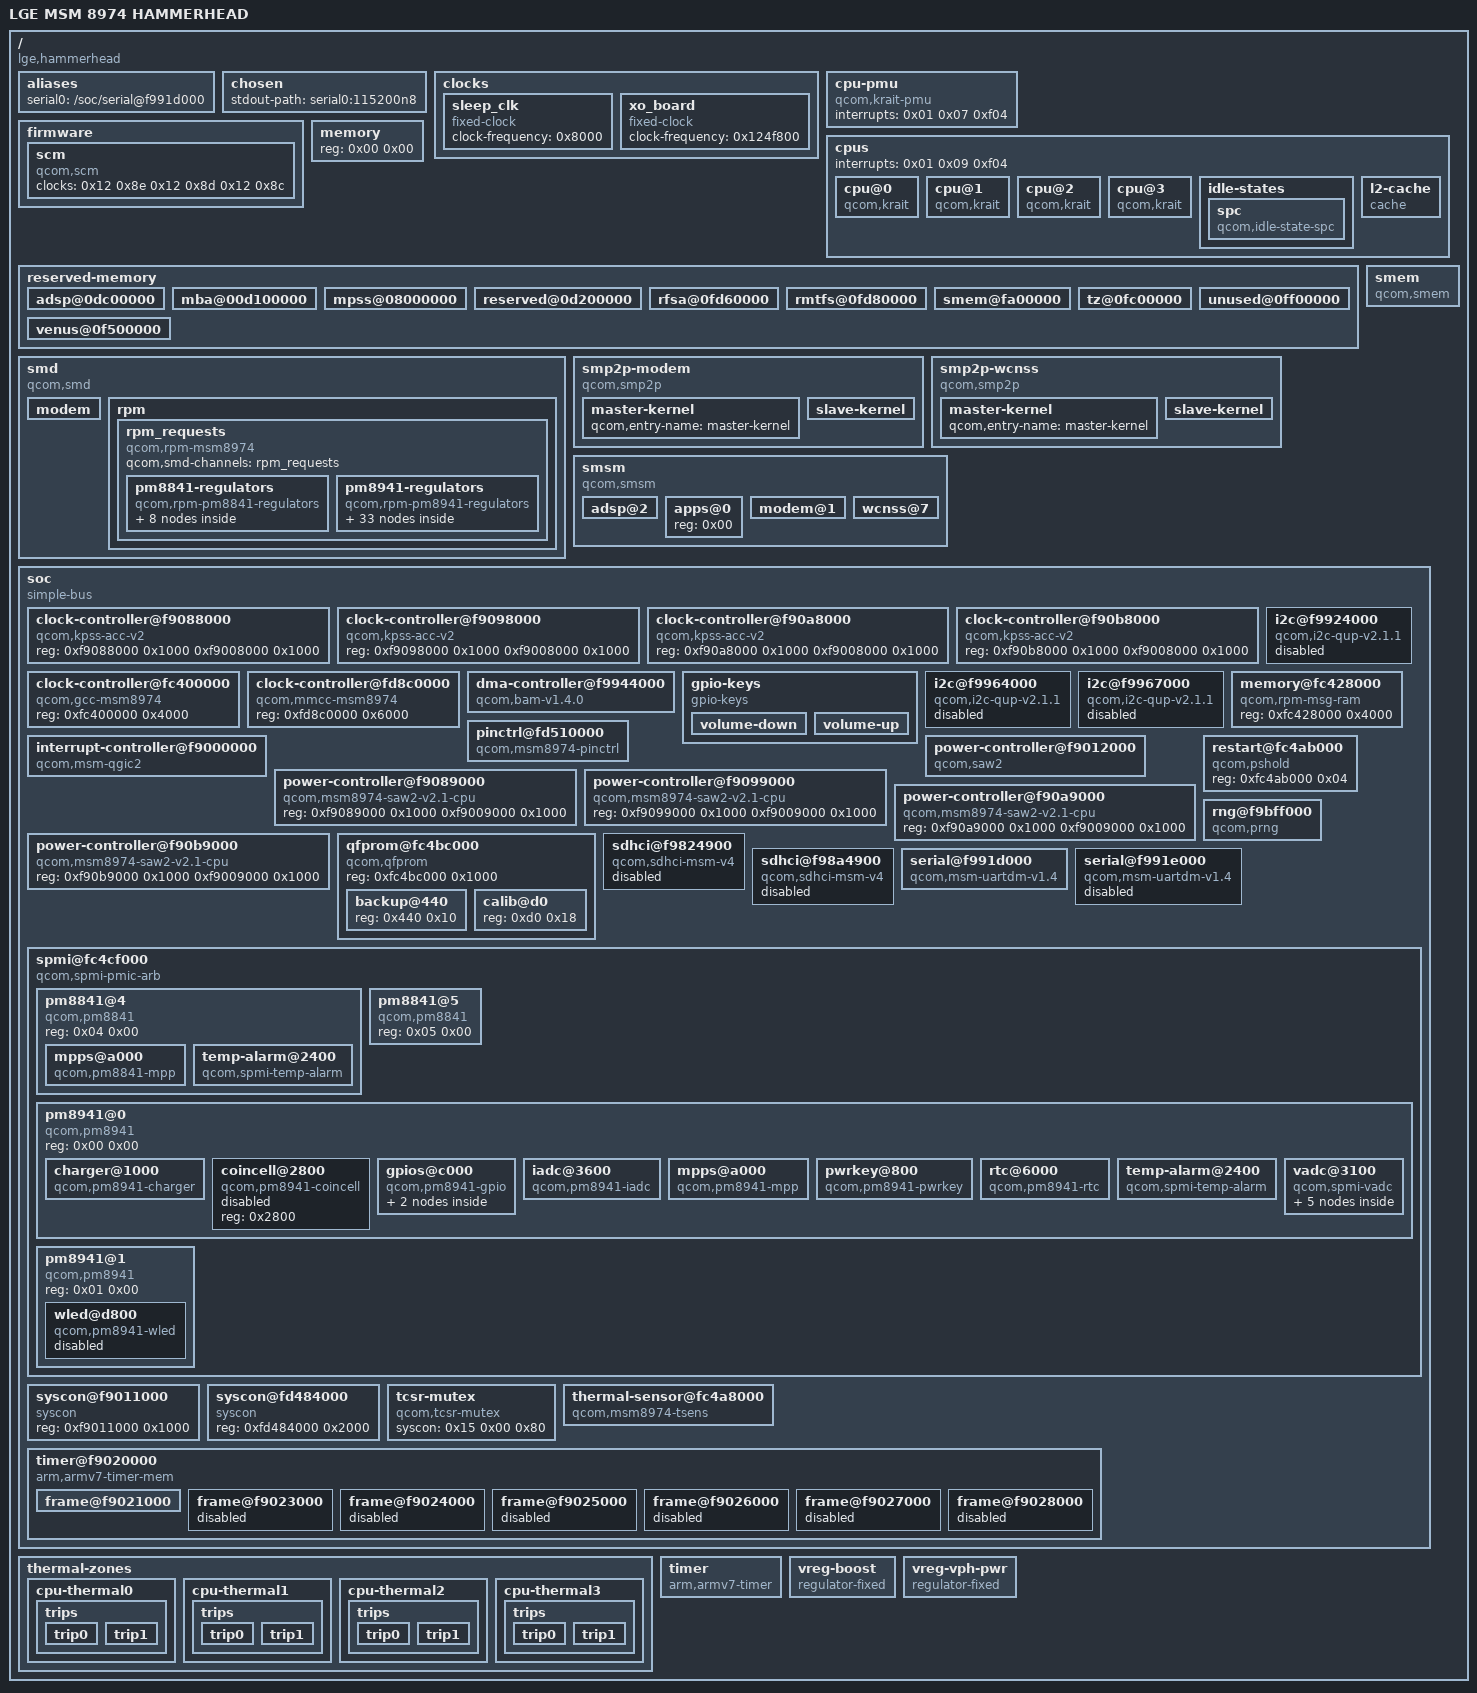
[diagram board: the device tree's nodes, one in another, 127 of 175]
/dts-v1/;

/ {
	#address-cells = <0x01>;
	#size-cells = <0x01>;
	compatible = "lge,hammerhead\0qcom,msm8974";
	interrupt-parent = <0x01>;
	model = "LGE MSM 8974 HAMMERHEAD";

	__symbols__ {
		CPU_SPC = "/cpus/idle-states/spc";
		L2 = "/cpus/l2-cache";
		acc0 = "/soc/clock-controller@f9088000";
		acc1 = "/soc/clock-controller@f9098000";
		acc2 = "/soc/clock-controller@f90a8000";
		acc3 = "/soc/clock-controller@f90b8000";
		adsp_smsm = "/smsm/adsp@2";
		apcs = "/soc/syscon@f9011000";
		apps_smsm = "/smsm/apps@0";
		blsp1_uart1 = "/soc/serial@f991d000";
		blsp1_uart2 = "/soc/serial@f991e000";
		blsp2_dma = "/soc/dma-controller@f9944000";
		blsp_i2c11 = "/soc/i2c@f9967000";
		blsp_i2c8 = "/soc/i2c@f9964000";
		boost_bypass_n_pin = "/soc/spmi@fc4cf000/pm8941@0/gpios@c000/boost-bypass";
		cpu_alert0 = "/thermal-zones/cpu-thermal0/trips/trip0";
		cpu_alert1 = "/thermal-zones/cpu-thermal1/trips/trip0";
		cpu_alert2 = "/thermal-zones/cpu-thermal2/trips/trip0";
		cpu_alert3 = "/thermal-zones/cpu-thermal3/trips/trip0";
		cpu_crit0 = "/thermal-zones/cpu-thermal0/trips/trip1";
		cpu_crit1 = "/thermal-zones/cpu-thermal1/trips/trip1";
		cpu_crit2 = "/thermal-zones/cpu-thermal2/trips/trip1";
		cpu_crit3 = "/thermal-zones/cpu-thermal3/trips/trip1";
		gcc = "/soc/clock-controller@fc400000";
		gpio_keys_pin_a = "/soc/spmi@fc4cf000/pm8941@0/gpios@c000/gpio-keys-active";
		intc = "/soc/interrupt-controller@f9000000";
		mmcc = "/soc/clock-controller@fd8c0000";
		modem_smp2p_in = "/smp2p-modem/slave-kernel";
		modem_smp2p_out = "/smp2p-modem/master-kernel";
		modem_smsm = "/smsm/modem@1";
		msmgpio = "/soc/pinctrl@fd510000";
		pm8841_0 = "/soc/spmi@fc4cf000/pm8841@4";
		pm8841_1 = "/soc/spmi@fc4cf000/pm8841@5";
		pm8841_mpps = "/soc/spmi@fc4cf000/pm8841@4/mpps@a000";
		pm8841_s1 = "/smd/rpm/rpm_requests/pm8841-regulators/s1";
		pm8841_s2 = "/smd/rpm/rpm_requests/pm8841-regulators/s2";
		pm8841_s3 = "/smd/rpm/rpm_requests/pm8841-regulators/s3";
		pm8841_s4 = "/smd/rpm/rpm_requests/pm8841-regulators/s4";
		pm8841_s5 = "/smd/rpm/rpm_requests/pm8841-regulators/s5";
		pm8841_s6 = "/smd/rpm/rpm_requests/pm8841-regulators/s6";
		pm8841_s7 = "/smd/rpm/rpm_requests/pm8841-regulators/s7";
		pm8841_s8 = "/smd/rpm/rpm_requests/pm8841-regulators/s8";
		pm8941_0 = "/soc/spmi@fc4cf000/pm8941@0";
		pm8941_1 = "/soc/spmi@fc4cf000/pm8941@1";
		pm8941_5v = "/smd/rpm/rpm_requests/pm8941-regulators/s4";
		pm8941_5vs1 = "/smd/rpm/rpm_requests/pm8941-regulators/5vs1";
		pm8941_5vs2 = "/smd/rpm/rpm_requests/pm8941-regulators/5vs2";
		pm8941_gpios = "/soc/spmi@fc4cf000/pm8941@0/gpios@c000";
		pm8941_iadc = "/soc/spmi@fc4cf000/pm8941@0/iadc@3600";
		pm8941_l1 = "/smd/rpm/rpm_requests/pm8941-regulators/l1";
		pm8941_l10 = "/smd/rpm/rpm_requests/pm8941-regulators/l10";
		pm8941_l11 = "/smd/rpm/rpm_requests/pm8941-regulators/l11";
		pm8941_l12 = "/smd/rpm/rpm_requests/pm8941-regulators/l12";
		pm8941_l13 = "/smd/rpm/rpm_requests/pm8941-regulators/l13";
		pm8941_l14 = "/smd/rpm/rpm_requests/pm8941-regulators/l14";
		pm8941_l15 = "/smd/rpm/rpm_requests/pm8941-regulators/l15";
		pm8941_l16 = "/smd/rpm/rpm_requests/pm8941-regulators/l16";
		pm8941_l17 = "/smd/rpm/rpm_requests/pm8941-regulators/l17";
		pm8941_l18 = "/smd/rpm/rpm_requests/pm8941-regulators/l18";
		pm8941_l19 = "/smd/rpm/rpm_requests/pm8941-regulators/l19";
		pm8941_l2 = "/smd/rpm/rpm_requests/pm8941-regulators/l2";
		pm8941_l20 = "/smd/rpm/rpm_requests/pm8941-regulators/l20";
		pm8941_l21 = "/smd/rpm/rpm_requests/pm8941-regulators/l21";
		pm8941_l22 = "/smd/rpm/rpm_requests/pm8941-regulators/l22";
		pm8941_l23 = "/smd/rpm/rpm_requests/pm8941-regulators/l23";
		pm8941_l24 = "/smd/rpm/rpm_requests/pm8941-regulators/l24";
		pm8941_l3 = "/smd/rpm/rpm_requests/pm8941-regulators/l3";
		pm8941_l4 = "/smd/rpm/rpm_requests/pm8941-regulators/l4";
		pm8941_l5 = "/smd/rpm/rpm_requests/pm8941-regulators/l5";
		pm8941_l6 = "/smd/rpm/rpm_requests/pm8941-regulators/l6";
		pm8941_l7 = "/smd/rpm/rpm_requests/pm8941-regulators/l7";
		pm8941_l8 = "/smd/rpm/rpm_requests/pm8941-regulators/l8";
		pm8941_l9 = "/smd/rpm/rpm_requests/pm8941-regulators/l9";
		pm8941_lvs1 = "/smd/rpm/rpm_requests/pm8941-regulators/lvs1";
		pm8941_lvs2 = "/smd/rpm/rpm_requests/pm8941-regulators/lvs2";
		pm8941_lvs3 = "/smd/rpm/rpm_requests/pm8941-regulators/lvs3";
		pm8941_mpps = "/soc/spmi@fc4cf000/pm8941@0/mpps@a000";
		pm8941_s1 = "/smd/rpm/rpm_requests/pm8941-regulators/s1";
		pm8941_s2 = "/smd/rpm/rpm_requests/pm8941-regulators/s2";
		pm8941_s3 = "/smd/rpm/rpm_requests/pm8941-regulators/s3";
		pm8941_temp = "/soc/spmi@fc4cf000/pm8941@0/temp-alarm@2400";
		pm8941_vadc = "/soc/spmi@fc4cf000/pm8941@0/vadc@3100";
		pm8941_wled = "/soc/spmi@fc4cf000/pm8941@1/wled@d800";
		qfprom = "/soc/qfprom@fc4bc000";
		rpm_msg_ram = "/soc/memory@fc428000";
		saw0 = "/soc/power-controller@f9089000";
		saw1 = "/soc/power-controller@f9099000";
		saw2 = "/soc/power-controller@f90a9000";
		saw3 = "/soc/power-controller@f90b9000";
		saw_l2 = "/soc/power-controller@f9012000";
		smem_region = "/reserved-memory/smem@fa00000";
		soc = "/soc";
		spmi_bus = "/soc/spmi@fc4cf000";
		tcsr_mutex = "/soc/tcsr-mutex";
		tcsr_mutex_block = "/soc/syscon@fd484000";
		tsens = "/soc/thermal-sensor@fc4a8000";
		tsens_backup = "/soc/qfprom@fc4bc000/backup@440";
		tsens_calib = "/soc/qfprom@fc4bc000/calib@d0";
		vreg_boost = "/vreg-boost";
		vreg_vph_pwr = "/vreg-vph-pwr";
		wcnss_smp2p_in = "/smp2p-wcnss/slave-kernel";
		wcnss_smp2p_out = "/smp2p-wcnss/master-kernel";
		wcnss_smsm = "/smsm/wcnss@7";
	};

	aliases {
		serial0 = "/soc/serial@f991d000";
	};

	chosen {
		stdout-path = "serial0:115200n8";
	};

	clocks {

		sleep_clk {
			#clock-cells = <0x00>;
			clock-frequency = <0x8000>;
			compatible = "fixed-clock";
		};

		xo_board {
			#clock-cells = <0x00>;
			clock-frequency = <0x124f800>;
			compatible = "fixed-clock";
		};
	};

	cpu-pmu {
		compatible = "qcom,krait-pmu";
		interrupts = <0x01 0x07 0xf04>;
	};

	cpus {
		#address-cells = <0x01>;
		#size-cells = <0x00>;
		interrupts = <0x01 0x09 0xf04>;

		cpu@0 {
			compatible = "qcom,krait";
			cpu-idle-states = <0x05>;
			device_type = "cpu";
			enable-method = "qcom,kpss-acc-v2";
			next-level-cache = <0x02>;
			qcom,acc = <0x03>;
			qcom,saw = <0x04>;
			reg = <0x00>;
		};

		cpu@1 {
			compatible = "qcom,krait";
			cpu-idle-states = <0x05>;
			device_type = "cpu";
			enable-method = "qcom,kpss-acc-v2";
			next-level-cache = <0x02>;
			qcom,acc = <0x06>;
			qcom,saw = <0x07>;
			reg = <0x01>;
		};

		cpu@2 {
			compatible = "qcom,krait";
			cpu-idle-states = <0x05>;
			device_type = "cpu";
			enable-method = "qcom,kpss-acc-v2";
			next-level-cache = <0x02>;
			qcom,acc = <0x08>;
			qcom,saw = <0x09>;
			reg = <0x02>;
		};

		cpu@3 {
			compatible = "qcom,krait";
			cpu-idle-states = <0x05>;
			device_type = "cpu";
			enable-method = "qcom,kpss-acc-v2";
			next-level-cache = <0x02>;
			qcom,acc = <0x0a>;
			qcom,saw = <0x0b>;
			reg = <0x03>;
		};

		idle-states {

			spc {
				compatible = "qcom,idle-state-spc\0arm,idle-state";
				entry-latency-us = <0x96>;
				exit-latency-us = <0xc8>;
				min-residency-us = <0x7d0>;
				phandle = <0x05>;
			};
		};

		l2-cache {
			cache-level = <0x02>;
			compatible = "cache";
			phandle = <0x02>;
			qcom,saw = <0x0c>;
		};
	};

	firmware {

		scm {
			clock-names = "core\0bus\0iface";
			clocks = <0x12 0x8e 0x12 0x8d 0x12 0x8c>;
			compatible = "qcom,scm";
		};
	};

	memory {
		device_type = "memory";
		reg = <0x00 0x00>;
	};

	reserved-memory {
		#address-cells = <0x01>;
		#size-cells = <0x01>;
		ranges;

		adsp@0dc00000 {
			no-map;
			reg = <0xdc00000 0x1900000>;
		};

		mba@00d100000 {
			no-map;
			reg = <0xd100000 0x100000>;
		};

		mpss@08000000 {
			no-map;
			reg = <0x8000000 0x5100000>;
		};

		reserved@0d200000 {
			no-map;
			reg = <0xd200000 0xa00000>;
		};

		rfsa@0fd60000 {
			no-map;
			reg = <0xfd60000 0x20000>;
		};

		rmtfs@0fd80000 {
			no-map;
			reg = <0xfd80000 0x180000>;
		};

		smem@fa00000 {
			no-map;
			phandle = <0x0e>;
			reg = <0xfa00000 0x200000>;
		};

		tz@0fc00000 {
			no-map;
			reg = <0xfc00000 0x160000>;
		};

		unused@0ff00000 {
			no-map;
			reg = <0xff00000 0x10100000>;
		};

		venus@0f500000 {
			no-map;
			reg = <0xf500000 0x500000>;
		};
	};

	smd {
		compatible = "qcom,smd";

		modem {
			interrupts = <0x00 0x19 0x01>;
			qcom,ipc = <0x11 0x08 0x0c>;
			qcom,smd-edge = <0x00>;
		};

		rpm {
			interrupts = <0x00 0xa8 0x01>;
			qcom,ipc = <0x11 0x08 0x00>;
			qcom,smd-edge = <0x0f>;

			rpm_requests {
				compatible = "qcom,rpm-msm8974";
				qcom,smd-channels = "rpm_requests";

				pm8841-regulators {
					compatible = "qcom,rpm-pm8841-regulators";

					s1 {
						phandle = <0x42>;
						regulator-max-microvolt = <0x100590>;
						regulator-min-microvolt = <0xa4cb8>;
					};

					s2 {
						phandle = <0x43>;
						regulator-max-microvolt = <0x100590>;
						regulator-min-microvolt = <0x7a120>;
					};

					s3 {
						phandle = <0x44>;
						regulator-max-microvolt = <0x100590>;
						regulator-min-microvolt = <0x100590>;
					};

					s4 {
						phandle = <0x45>;
						regulator-max-microvolt = <0xdbba0>;
						regulator-min-microvolt = <0xc6f98>;
					};

					s5 {
						phandle = <0x46>;
					};

					s6 {
						phandle = <0x47>;
					};

					s7 {
						phandle = <0x48>;
					};

					s8 {
						phandle = <0x49>;
					};
				};

				pm8941-regulators {
					compatible = "qcom,rpm-pm8941-regulators";
					vdd_l13_l20_l23_l24-supply = <0x1e>;
					vdd_l1_l3-supply = <0x1a>;
					vdd_l21-supply = <0x1e>;
					vdd_l2_lvs1_2_3-supply = <0x1b>;
					vdd_l4_l11-supply = <0x1a>;
					vdd_l5_l7-supply = <0x1c>;
					vdd_l6_l12_l14_l15-supply = <0x1c>;
					vdd_l8_l16_l18_l19-supply = <0x1d>;
					vdd_l9_l10_l17_l22-supply = <0x1e>;

					5vs1 {
						phandle = <0x66>;
					};

					5vs2 {
						phandle = <0x67>;
					};

					l1 {
						phandle = <0x4b>;
						regulator-always-on;
						regulator-boot-on;
						regulator-max-microvolt = <0x12b128>;
						regulator-min-microvolt = <0x12b128>;
					};

					l10 {
						phandle = <0x54>;
						regulator-max-microvolt = <0x2d0370>;
						regulator-min-microvolt = <0x1b7740>;
					};

					l11 {
						phandle = <0x55>;
						regulator-max-microvolt = <0x13d620>;
						regulator-min-microvolt = <0x13d620>;
					};

					l12 {
						phandle = <0x56>;
						regulator-always-on;
						regulator-boot-on;
						regulator-max-microvolt = <0x1b7740>;
						regulator-min-microvolt = <0x1b7740>;
					};

					l13 {
						phandle = <0x57>;
						regulator-boot-on;
						regulator-max-microvolt = <0x2d0370>;
						regulator-min-microvolt = <0x1b7740>;
					};

					l14 {
						phandle = <0x58>;
						regulator-max-microvolt = <0x1b7740>;
						regulator-min-microvolt = <0x1b7740>;
					};

					l15 {
						phandle = <0x59>;
						regulator-max-microvolt = <0x1f47d0>;
						regulator-min-microvolt = <0x1f47d0>;
					};

					l16 {
						phandle = <0x5a>;
						regulator-max-microvolt = <0x2932e0>;
						regulator-min-microvolt = <0x2932e0>;
					};

					l17 {
						phandle = <0x5b>;
						regulator-max-microvolt = <0x2b7cd0>;
						regulator-min-microvolt = <0x2b7cd0>;
					};

					l18 {
						phandle = <0x5c>;
						regulator-max-microvolt = <0x2b7cd0>;
						regulator-min-microvolt = <0x2b7cd0>;
					};

					l19 {
						phandle = <0x5d>;
						regulator-max-microvolt = <0x325aa0>;
						regulator-min-microvolt = <0x2dc6c0>;
					};

					l2 {
						phandle = <0x4c>;
						regulator-max-microvolt = <0x124f80>;
						regulator-min-microvolt = <0x124f80>;
					};

					l20 {
						phandle = <0x5e>;
						regulator-allow-set-load;
						regulator-boot-on;
						regulator-max-microvolt = <0x2d0370>;
						regulator-min-microvolt = <0x2d0370>;
						regulator-system-load = <0x30d40>;
					};

					l21 {
						phandle = <0x5f>;
						regulator-boot-on;
						regulator-max-microvolt = <0x2d0370>;
						regulator-min-microvolt = <0x2d0370>;
					};

					l22 {
						phandle = <0x60>;
						regulator-max-microvolt = <0x325aa0>;
						regulator-min-microvolt = <0x2dc6c0>;
					};

					l23 {
						phandle = <0x61>;
						regulator-max-microvolt = <0x2dc6c0>;
						regulator-min-microvolt = <0x2dc6c0>;
					};

					l24 {
						phandle = <0x62>;
						regulator-boot-on;
						regulator-max-microvolt = <0x2eebb8>;
						regulator-min-microvolt = <0x2eebb8>;
					};

					l3 {
						phandle = <0x4d>;
						regulator-max-microvolt = <0x12b128>;
						regulator-min-microvolt = <0x12b128>;
					};

					l4 {
						phandle = <0x4e>;
						regulator-max-microvolt = <0x12b128>;
						regulator-min-microvolt = <0x12b128>;
					};

					l5 {
						phandle = <0x4f>;
						regulator-max-microvolt = <0x1b7740>;
						regulator-min-microvolt = <0x1b7740>;
					};

					l6 {
						phandle = <0x50>;
						regulator-boot-on;
						regulator-max-microvolt = <0x1b7740>;
						regulator-min-microvolt = <0x1b7740>;
					};

					l7 {
						phandle = <0x51>;
						regulator-boot-on;
						regulator-max-microvolt = <0x1b7740>;
						regulator-min-microvolt = <0x1b7740>;
					};

					l8 {
						phandle = <0x52>;
						regulator-max-microvolt = <0x1b7740>;
						regulator-min-microvolt = <0x1b7740>;
					};

					l9 {
						phandle = <0x53>;
						regulator-max-microvolt = <0x2d0370>;
						regulator-min-microvolt = <0x1b7740>;
					};

					lvs1 {
						phandle = <0x63>;
					};

					lvs2 {
						phandle = <0x64>;
					};

					lvs3 {
						phandle = <0x65>;
					};

					s1 {
						phandle = <0x1a>;
						regulator-always-on;
						regulator-boot-on;
						regulator-max-microvolt = <0x13d620>;
						regulator-min-microvolt = <0x13d620>;
					};

					s2 {
						phandle = <0x1c>;
						regulator-boot-on;
						regulator-max-microvolt = <0x20ce70>;
						regulator-min-microvolt = <0x20ce70>;
					};

					s3 {
						phandle = <0x1b>;
						regulator-always-on;
						regulator-boot-on;
						regulator-max-microvolt = <0x1b7740>;
						regulator-min-microvolt = <0x1b7740>;
					};

					s4 {
						phandle = <0x4a>;
					};
				};
			};
		};
	};

	smem {
		compatible = "qcom,smem";
		hwlocks = <0x10 0x03>;
		memory-region = <0x0e>;
		qcom,rpm-msg-ram = <0x0f>;
	};

	smp2p-modem {
		compatible = "qcom,smp2p";
		interrupt-parent = <0x01>;
		interrupts = <0x00 0x1b 0x01>;
		qcom,ipc = <0x11 0x08 0x0e>;
		qcom,local-pid = <0x00>;
		qcom,remote-pid = <0x01>;
		qcom,smem = <0x1b3 0x1ac>;

		master-kernel {
			#qcom,smem-state-cells = <0x01>;
			phandle = <0x28>;
			qcom,entry-name = "master-kernel";
		};

		slave-kernel {
			#interrupt-cells = <0x02>;
			interrupt-controller;
			phandle = <0x29>;
			qcom,entry-name = "slave-kernel";
		};
	};

	smp2p-wcnss {
		compatible = "qcom,smp2p";
		interrupt-parent = <0x01>;
		interrupts = <0x00 0x8f 0x01>;
		qcom,ipc = <0x11 0x08 0x12>;
		qcom,local-pid = <0x00>;
		qcom,remote-pid = <0x04>;
		qcom,smem = <0x1c3 0x1af>;

		master-kernel {
			#qcom,smem-state-cells = <0x01>;
			phandle = <0x2a>;
			qcom,entry-name = "master-kernel";
		};

		slave-kernel {
			#interrupt-cells = <0x02>;
			interrupt-controller;
			phandle = <0x2b>;
			qcom,entry-name = "slave-kernel";
		};
	};

	smsm {
		#address-cells = <0x01>;
		#size-cells = <0x00>;
		compatible = "qcom,smsm";
		qcom,ipc-1 = <0x11 0x08 0x0d>;
		qcom,ipc-2 = <0x11 0x08 0x09>;
		qcom,ipc-3 = <0x11 0x08 0x13>;

		adsp@2 {
			#interrupt-cells = <0x02>;
			interrupt-controller;
			interrupts = <0x00 0x9d 0x01>;
			phandle = <0x2e>;
			reg = <0x02>;
		};

		apps@0 {
			#qcom,smem-state-cells = <0x01>;
			phandle = <0x2c>;
			reg = <0x00>;
		};

		modem@1 {
			#interrupt-cells = <0x02>;
			interrupt-controller;
			interrupts = <0x00 0x1a 0x01>;
			phandle = <0x2d>;
			reg = <0x01>;
		};

		wcnss@7 {
			#interrupt-cells = <0x02>;
			interrupt-controller;
			interrupts = <0x00 0x90 0x01>;
			phandle = <0x2f>;
			reg = <0x07>;
		};
	};

	soc {
		#address-cells = <0x01>;
		#size-cells = <0x01>;
		compatible = "simple-bus";
		phandle = <0x30>;
		ranges;

		clock-controller@f9088000 {
			compatible = "qcom,kpss-acc-v2";
			phandle = <0x03>;
			reg = <0xf9088000 0x1000 0xf9008000 0x1000>;
		};

		clock-controller@f9098000 {
			compatible = "qcom,kpss-acc-v2";
			phandle = <0x06>;
			reg = <0xf9098000 0x1000 0xf9008000 0x1000>;
		};

		clock-controller@f90a8000 {
			compatible = "qcom,kpss-acc-v2";
			phandle = <0x08>;
			reg = <0xf90a8000 0x1000 0xf9008000 0x1000>;
		};

		clock-controller@f90b8000 {
			compatible = "qcom,kpss-acc-v2";
			phandle = <0x0a>;
			reg = <0xf90b8000 0x1000 0xf9008000 0x1000>;
		};

		clock-controller@fc400000 {
			#clock-cells = <0x01>;
			#power-domain-cells = <0x01>;
			#reset-cells = <0x01>;
			compatible = "qcom,gcc-msm8974";
			phandle = <0x12>;
			reg = <0xfc400000 0x4000>;
		};

		clock-controller@fd8c0000 {
			#clock-cells = <0x01>;
			#power-domain-cells = <0x01>;
			#reset-cells = <0x01>;
			compatible = "qcom,mmcc-msm8974";
			phandle = <0x32>;
			reg = <0xfd8c0000 0x6000>;
		};

		dma-controller@f9944000 {
			#dma-cells = <0x01>;
			clock-names = "bam_clk";
			clocks = <0x12 0x71>;
			compatible = "qcom,bam-v1.4.0";
			interrupts = <0x00 0xef 0x04>;
			phandle = <0x16>;
			qcom,ee = <0x00>;
			reg = <0xf9944000 0x19000>;
		};

		gpio-keys {
			compatible = "gpio-keys";
			input-name = "gpio-keys";
			pinctrl-0 = <0x18>;
			pinctrl-names = "default";

			volume-down {
				gpios = <0x19 0x03 0x01>;
				label = "volume_down";
				linux,code = <0x72>;
				linux,input-type = <0x01>;
			};

			volume-up {
				gpios = <0x19 0x02 0x01>;
				label = "volume_up";
				linux,code = <0x73>;
				linux,input-type = <0x01>;
			};
		};

		i2c@f9924000 {
			#address-cells = <0x01>;
			#size-cells = <0x00>;
			clock-names = "core\0iface";
			clocks = <0x12 0x5b 0x12 0x57>;
			compatible = "qcom,i2c-qup-v2.1.1";
			interrupts = <0x00 0x60 0x00>;
			reg = <0xf9924000 0x1000>;
			status = "disabled";
		};

		i2c@f9964000 {
			#address-cells = <0x01>;
			#size-cells = <0x00>;
			clock-names = "core\0iface";
			clocks = <0x12 0x75 0x12 0x71>;
			compatible = "qcom,i2c-qup-v2.1.1";
			interrupts = <0x00 0x66 0x00>;
			phandle = <0x36>;
			reg = <0xf9964000 0x1000>;
			status = "disabled";
		};

		i2c@f9967000 {
			#address-cells = <0x01>;
			#size-cells = <0x00>;
			clock-names = "core\0iface";
			clocks = <0x12 0x7b 0x12 0x71>;
			compatible = "qcom,i2c-qup-v2.1.1";
			dma-names = "tx\0rx";
			dmas = <0x16 0x14 0x16 0x15>;
			interrupts = <0x00 0x69 0x00>;
			phandle = <0x37>;
			reg = <0xf9967000 0x1000>;
			status = "disabled";
		};

		interrupt-controller@f9000000 {
			#interrupt-cells = <0x03>;
			compatible = "qcom,msm-qgic2";
			interrupt-controller;
			phandle = <0x01>;
			reg = <0xf9000000 0x1000 0xf9002000 0x1000>;
		};

		memory@fc428000 {
			compatible = "qcom,rpm-msg-ram";
			phandle = <0x0f>;
			reg = <0xfc428000 0x4000>;
		};

		pinctrl@fd510000 {
			#gpio-cells = <0x02>;
			#interrupt-cells = <0x02>;
			compatible = "qcom,msm8974-pinctrl";
			gpio-controller;
			interrupt-controller;
			interrupts = <0x00 0xd0 0x00>;
			phandle = <0x35>;
			reg = <0xfd510000 0x4000>;
		};

		power-controller@f9012000 {
			compatible = "qcom,saw2";
			phandle = <0x0c>;
			reg = <0xf9012000 0x1000>;
			regulator;
		};

		power-controller@f9089000 {
			compatible = "qcom,msm8974-saw2-v2.1-cpu\0qcom,saw2";
			phandle = <0x04>;
			reg = <0xf9089000 0x1000 0xf9009000 0x1000>;
		};

		power-controller@f9099000 {
			compatible = "qcom,msm8974-saw2-v2.1-cpu\0qcom,saw2";
			phandle = <0x07>;
			reg = <0xf9099000 0x1000 0xf9009000 0x1000>;
		};

		power-controller@f90a9000 {
			compatible = "qcom,msm8974-saw2-v2.1-cpu\0qcom,saw2";
			phandle = <0x09>;
			reg = <0xf90a9000 0x1000 0xf9009000 0x1000>;
		};

		power-controller@f90b9000 {
			compatible = "qcom,msm8974-saw2-v2.1-cpu\0qcom,saw2";
			phandle = <0x0b>;
			reg = <0xf90b9000 0x1000 0xf9009000 0x1000>;
		};

		qfprom@fc4bc000 {
			#address-cells = <0x01>;
			#size-cells = <0x01>;
			compatible = "qcom,qfprom";
			phandle = <0x31>;
			reg = <0xfc4bc000 0x1000>;

			backup@440 {
				phandle = <0x14>;
				reg = <0x440 0x10>;
			};

			calib@d0 {
				phandle = <0x13>;
				reg = <0xd0 0x18>;
			};
		};

		restart@fc4ab000 {
			compatible = "qcom,pshold";
			reg = <0xfc4ab000 0x04>;
		};

		rng@f9bff000 {
			clock-names = "core";
			clocks = <0x12 0xc3>;
			compatible = "qcom,prng";
			reg = <0xf9bff000 0x200>;
		};

		sdhci@f9824900 {
			clock-names = "core\0iface";
			clocks = <0x12 0xd8 0x12 0xd7>;
			compatible = "qcom,sdhci-msm-v4";
			interrupt-names = "hc_irq\0pwr_irq";
			interrupts = <0x00 0x7b 0x00 0x00 0x8a 0x00>;
			reg = <0xf9824900 0x11c 0xf9824000 0x800>;
			reg-names = "hc_mem\0core_mem";
			status = "disabled";
		};

		sdhci@f98a4900 {
			clock-names = "core\0iface";
			clocks = <0x12 0xdb 0x12 0xda>;
			compatible = "qcom,sdhci-msm-v4";
			interrupt-names = "hc_irq\0pwr_irq";
			interrupts = <0x00 0x7d 0x00 0x00 0xdd 0x00>;
			reg = <0xf98a4900 0x11c 0xf98a4000 0x800>;
			reg-names = "hc_mem\0core_mem";
			status = "disabled";
		};

		serial@f991d000 {
			clock-names = "core\0iface";
			clocks = <0x12 0x65 0x12 0x57>;
			compatible = "qcom,msm-uartdm-v1.4\0qcom,msm-uartdm";
			interrupts = <0x00 0x6b 0x00>;
			phandle = <0x33>;
			reg = <0xf991d000 0x1000>;
			status = "ok";
		};

		serial@f991e000 {
			clock-names = "core\0iface";
			clocks = <0x12 0x67 0x12 0x57>;
			compatible = "qcom,msm-uartdm-v1.4\0qcom,msm-uartdm";
			interrupts = <0x00 0x6c 0x00>;
			phandle = <0x34>;
			reg = <0xf991e000 0x1000>;
			status = "disabled";
		};

		spmi@fc4cf000 {
			#address-cells = <0x02>;
			#interrupt-cells = <0x04>;
			#size-cells = <0x00>;
			compatible = "qcom,spmi-pmic-arb";
			interrupt-controller;
			interrupt-names = "periph_irq";
			interrupts = <0x00 0xbe 0x00>;
			phandle = <0x38>;
			qcom,channel = <0x00>;
			qcom,ee = <0x00>;
			reg = <0xfc4cf000 0x1000 0xfc4cb000 0x1000 0xfc4ca000 0x1000>;
			reg-names = "core\0intr\0cnfg";

			pm8841@4 {
				#address-cells = <0x01>;
				#size-cells = <0x00>;
				compatible = "qcom,pm8841\0qcom,spmi-pmic";
				phandle = <0x39>;
				reg = <0x04 0x00>;

				mpps@a000 {
					#gpio-cells = <0x02>;
					compatible = "qcom,pm8841-mpp\0qcom,spmi-mpp";
					gpio-controller;
					interrupts = <0x04 0xa0 0x00 0x00 0x04 0xa1 0x00 0x00 0x04 0xa2 0x00 0x00 0x04 0xa3 0x00 0x00>;
					phandle = <0x3a>;
					reg = <0xa000>;
				};

				temp-alarm@2400 {
					compatible = "qcom,spmi-temp-alarm";
					interrupts = <0x04 0x24 0x00 0x01>;
					reg = <0x2400>;
				};
			};

			pm8841@5 {
				#address-cells = <0x01>;
				#size-cells = <0x00>;
				compatible = "qcom,pm8841\0qcom,spmi-pmic";
				phandle = <0x3b>;
				reg = <0x05 0x00>;
			};

			pm8941@0 {
				#address-cells = <0x01>;
				#size-cells = <0x00>;
				compatible = "qcom,pm8941\0qcom,spmi-pmic";
				phandle = <0x3c>;
				reg = <0x00 0x00>;

				charger@1000 {
					compatible = "qcom,pm8941-charger";
					interrupt-names = "chg-done\0chg-fast\0chg-trkl\0bat-temp-ok\0bat-present\0chg-gone\0usb-valid\0dc-valid";
					interrupts = <0x00 0x10 0x07 0x03 0x00 0x10 0x05 0x03 0x00 0x10 0x04 0x03 0x00 0x12 0x01 0x03 0x00 0x12 0x00 0x03 0x00 0x13 0x02 0x03 0x00 0x13 0x01 0x03 0x00 0x14 0x01 0x03>;
					reg = <0x1000>;
				};

				coincell@2800 {
					compatible = "qcom,pm8941-coincell";
					reg = <0x2800>;
					status = "disabled";
				};

				gpios@c000 {
					#gpio-cells = <0x02>;
					compatible = "qcom,pm8941-gpio\0qcom,spmi-gpio";
					gpio-controller;
					interrupts = <0x00 0xc0 0x00 0x00 0x00 0xc1 0x00 0x00 0x00 0xc2 0x00 0x00 0x00 0xc3 0x00 0x00 0x00 0xc4 0x00 0x00 0x00 0xc5 0x00 0x00 0x00 0xc6 0x00 0x00 0x00 0xc7 0x00 0x00 0x00 0xc8 0x00 0x00 0x00 0xc9 0x00 0x00 0x00 0xca 0x00 0x00 0x00 0xcb 0x00 0x00 0x00 0xcc 0x00 0x00 0x00 0xcd 0x00 0x00 0x00 0xce 0x00 0x00 0x00 0xcf 0x00 0x00 0x00 0xd0 0x00 0x00 0x00 0xd1 0x00 0x00 0x00 0xd2 0x00 0x00 0x00 0xd3 0x00 0x00 0x00 0xd4 0x00 0x00 0x00 0xd5 0x00 0x00 0x00 0xd6 0x00 0x00 0x00 0xd7 0x00 0x00 0x00 0xd8 0x00 0x00 0x00 0xd9 0x00 0x00 0x00 0xda 0x00 0x00 0x00 0xdb 0x00 0x00 0x00 0xdc 0x00 0x00 0x00 0xdd 0x00 0x00 0x00 0xde 0x00 0x00 0x00 0xdf 0x00 0x00 0x00 0xe0 0x00 0x00 0x00 0xe1 0x00 0x00 0x00 0xe2 0x00 0x00 0x00 0xe3 0x00 0x00>;
					phandle = <0x19>;
					reg = <0xc000>;

					boost-bypass {
						function = "normal";
						phandle = <0x1f>;
						pins = "gpio21";
					};

					gpio-keys-active {
						bias-pull-up;
						function = "normal";
						phandle = <0x18>;
						pins = "gpio2\0gpio3";
						power-source = <0x02>;
					};
				};

				iadc@3600 {
					compatible = "qcom,pm8941-iadc\0qcom,spmi-iadc";
					interrupts = <0x00 0x36 0x00 0x01>;
					phandle = <0x3f>;
					qcom,external-resistor-micro-ohms = <0x2710>;
					reg = <0x3600>;
				};

				mpps@a000 {
					#gpio-cells = <0x02>;
					compatible = "qcom,pm8941-mpp\0qcom,spmi-mpp";
					gpio-controller;
					interrupts = <0x00 0xa0 0x00 0x00 0x00 0xa1 0x00 0x00 0x00 0xa2 0x00 0x00 0x00 0xa3 0x00 0x00 0x00 0xa4 0x00 0x00 0x00 0xa5 0x00 0x00 0x00 0xa6 0x00 0x00 0x00 0xa7 0x00 0x00>;
					phandle = <0x3d>;
					reg = <0xa000>;
				};

				pwrkey@800 {
					bias-pull-up;
					compatible = "qcom,pm8941-pwrkey";
					debounce = <0x3d09>;
					interrupts = <0x00 0x08 0x00 0x03>;
					reg = <0x800>;
				};

				rtc@6000 {
					compatible = "qcom,pm8941-rtc";
					interrupts = <0x00 0x61 0x01 0x01>;
					reg = <0x6000 0x6100>;
					reg-names = "rtc\0alarm";
				};

				temp-alarm@2400 {
					#thermal-sensor-cells = <0x00>;
					compatible = "qcom,spmi-temp-alarm";
					interrupts = <0x00 0x24 0x00 0x01>;
					io-channel-names = "thermal";
					io-channels = <0x17 0x08>;
					phandle = <0x3e>;
					reg = <0x2400>;
				};

				vadc@3100 {
					#address-cells = <0x01>;
					#io-channel-cells = <0x01>;
					#size-cells = <0x00>;
					compatible = "qcom,spmi-vadc";
					interrupts = <0x00 0x31 0x00 0x01>;
					phandle = <0x17>;
					reg = <0x3100>;

					die_temp {
						reg = <0x08>;
					};

					ref_1250v {
						reg = <0x0a>;
					};

					ref_625mv {
						reg = <0x09>;
					};

					ref_gnd {
						reg = <0x0e>;
					};

					ref_vdd {
						reg = <0x0f>;
					};
				};
			};

			pm8941@1 {
				#address-cells = <0x01>;
				#size-cells = <0x00>;
				compatible = "qcom,pm8941\0qcom,spmi-pmic";
				phandle = <0x40>;
				reg = <0x01 0x00>;

				wled@d800 {
					compatible = "qcom,pm8941-wled";
					label = "backlight";
					phandle = <0x41>;
					reg = <0xd800>;
					status = "disabled";
				};
			};
		};

		syscon@f9011000 {
			compatible = "syscon";
			phandle = <0x11>;
			reg = <0xf9011000 0x1000>;
		};

		syscon@fd484000 {
			compatible = "syscon";
			phandle = <0x15>;
			reg = <0xfd484000 0x2000>;
		};

		tcsr-mutex {
			#hwlock-cells = <0x01>;
			compatible = "qcom,tcsr-mutex";
			phandle = <0x10>;
			syscon = <0x15 0x00 0x80>;
		};

		thermal-sensor@fc4a8000 {
			#thermal-sensor-cells = <0x01>;
			compatible = "qcom,msm8974-tsens";
			nvmem-cell-names = "calib\0calib_backup";
			nvmem-cells = <0x13 0x14>;
			phandle = <0x0d>;
			reg = <0xfc4a8000 0x2000>;
		};

		timer@f9020000 {
			#address-cells = <0x01>;
			#size-cells = <0x01>;
			clock-frequency = <0x124f800>;
			compatible = "arm,armv7-timer-mem";
			ranges;
			reg = <0xf9020000 0x1000>;

			frame@f9021000 {
				frame-number = <0x00>;
				interrupts = <0x00 0x08 0x04 0x00 0x07 0x04>;
				reg = <0xf9021000 0x1000 0xf9022000 0x1000>;
			};

			frame@f9023000 {
				frame-number = <0x01>;
				interrupts = <0x00 0x09 0x04>;
				reg = <0xf9023000 0x1000>;
				status = "disabled";
			};

			frame@f9024000 {
				frame-number = <0x02>;
				interrupts = <0x00 0x0a 0x04>;
				reg = <0xf9024000 0x1000>;
				status = "disabled";
			};

			frame@f9025000 {
				frame-number = <0x03>;
				interrupts = <0x00 0x0b 0x04>;
				reg = <0xf9025000 0x1000>;
				status = "disabled";
			};

			frame@f9026000 {
				frame-number = <0x04>;
				interrupts = <0x00 0x0c 0x04>;
				reg = <0xf9026000 0x1000>;
				status = "disabled";
			};

			frame@f9027000 {
				frame-number = <0x05>;
				interrupts = <0x00 0x0d 0x04>;
				reg = <0xf9027000 0x1000>;
				status = "disabled";
			};

			frame@f9028000 {
				frame-number = <0x06>;
				interrupts = <0x00 0x0e 0x04>;
				reg = <0xf9028000 0x1000>;
				status = "disabled";
			};
		};
	};

	thermal-zones {

		cpu-thermal0 {
			polling-delay = <0x3e8>;
			polling-delay-passive = <0xfa>;
			thermal-sensors = <0x0d 0x05>;

			trips {

				trip0 {
					hysteresis = <0x7d0>;
					phandle = <0x20>;
					temperature = <0x124f8>;
					type = "passive";
				};

				trip1 {
					hysteresis = <0x7d0>;
					phandle = <0x21>;
					temperature = <0x1adb0>;
					type = "critical";
				};
			};
		};

		cpu-thermal1 {
			polling-delay = <0x3e8>;
			polling-delay-passive = <0xfa>;
			thermal-sensors = <0x0d 0x06>;

			trips {

				trip0 {
					hysteresis = <0x7d0>;
					phandle = <0x22>;
					temperature = <0x124f8>;
					type = "passive";
				};

				trip1 {
					hysteresis = <0x7d0>;
					phandle = <0x23>;
					temperature = <0x1adb0>;
					type = "critical";
				};
			};
		};

		cpu-thermal2 {
			polling-delay = <0x3e8>;
			polling-delay-passive = <0xfa>;
			thermal-sensors = <0x0d 0x07>;

			trips {

				trip0 {
					hysteresis = <0x7d0>;
					phandle = <0x24>;
					temperature = <0x124f8>;
					type = "passive";
				};

				trip1 {
					hysteresis = <0x7d0>;
					phandle = <0x25>;
					temperature = <0x1adb0>;
					type = "critical";
				};
			};
		};

		cpu-thermal3 {
			polling-delay = <0x3e8>;
			polling-delay-passive = <0xfa>;
			thermal-sensors = <0x0d 0x08>;

			trips {

				trip0 {
					hysteresis = <0x7d0>;
					phandle = <0x26>;
					temperature = <0x124f8>;
					type = "passive";
				};

				trip1 {
					hysteresis = <0x7d0>;
					phandle = <0x27>;
					temperature = <0x1adb0>;
					type = "critical";
				};
			};
		};
	};

	timer {
		clock-frequency = <0x124f800>;
		compatible = "arm,armv7-timer";
		interrupts = <0x01 0x02 0xf08 0x01 0x03 0xf08 0x01 0x04 0xf08 0x01 0x01 0xf08>;
	};

	vreg-boost {
		compatible = "regulator-fixed";
		enable-active-high;
		gpio = <0x19 0x15 0x00>;
		phandle = <0x1e>;
		pinctrl-0 = <0x1f>;
		pinctrl-names = "default";
		regulator-always-on;
		regulator-boot-on;
		regulator-max-microvolt = <0x3010b0>;
		regulator-min-microvolt = <0x3010b0>;
		regulator-name = "vreg-boost";
	};

	vreg-vph-pwr {
		compatible = "regulator-fixed";
		phandle = <0x1d>;
		regulator-always-on;
		regulator-max-microvolt = <0x36ee80>;
		regulator-min-microvolt = <0x36ee80>;
		regulator-name = "vph-pwr";
	};
};
